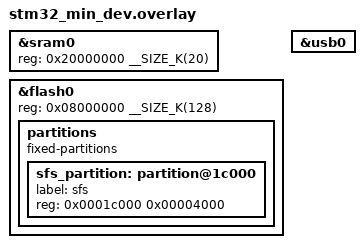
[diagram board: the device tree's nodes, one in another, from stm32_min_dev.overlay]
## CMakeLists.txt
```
include($ENV{ZEPHYR_BASE}/cmake/app/boilerplate.cmake NO_POLICY_SCOPE)
project(NONE)

add_definitions(-D_GLIBCXX_STDEXCEPT)

zephyr_include_directories(
  src
)

target_sources(app PRIVATE
  src/buf.c
  src/crypto.cpp
  src/hid.cpp
  src/main.cpp
  src/sfs.c
  src/u2f.cpp
  src/ui.cpp
  src/util.cpp
  src/crypto_sam0.cpp
)
```

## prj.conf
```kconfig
CONFIG_CPLUSPLUS=y
CONFIG_MAIN_STACK_SIZE=4096
CONFIG_SYSTEM_WORKQUEUE_STACK_SIZE=512
CONFIG_ISR_STACK_SIZE=1024

CONFIG_USB=y
CONFIG_USB_DEVICE_STACK=y
CONFIG_USB_DEVICE_HID=y

CONFIG_SYS_LOG=y
CONFIG_SYS_LOG_USB_DRIVER_LEVEL=1
CONFIG_SYS_LOG_USB_DEVICE_LEVEL=1

CONFIG_USB_DEVICE_VID=0x10c4
CONFIG_USB_DEVICE_PID=0x8acf
CONFIG_NET_BUF=y

CONFIG_INIT_STACKS=y

CONFIG_FLASH=y
CONFIG_SOC_FLASH_SAM0=y

CONFIG_DEBUG=y
CONFIG_ASSERT=y

CONFIG_FLASH_PAGE_LAYOUT=y
CONFIG_FILE_SYSTEM=y

CONFIG_MBEDTLS=y
CONFIG_MBEDTLS_BUILTIN=y
CONFIG_MBEDTLS_CFG_FILE="config-u2fzx.h"
CONFIG_MBEDTLS_ENABLE_HEAP=y
CONFIG_MBEDTLS_HEAP_SIZE=6500
```

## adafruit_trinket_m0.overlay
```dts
arduino_zero.overlay
```

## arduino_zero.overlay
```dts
&sercom0 {
	current-speed = <1000000>;
};

&flash0 {
	partitions {
		compatible = "fixed-partitions";
		#address-cells = <1>;
		#size-cells = <1>;

		sfs_partition: partition@3c000 {
			label = "sfs";
			reg = <0x0003c000 0x00004000>;
		};
	};
};
```

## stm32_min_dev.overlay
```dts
// / {
// 		zephyr,code-partition = &code_partition;
// };

&sram0 {
	reg = <0x20000000 __SIZE_K(20)>;
};

&flash0 {
	reg = <0x08000000 __SIZE_K(128)>;

	partitions {
		compatible = "fixed-partitions";
		#address-cells = <1>;
		#size-cells = <1>;

		// boot_partition: partition@0 {
		// 	label = "boot";
		// 	reg = <0x00000000 0x2000>;
		// 	read-only;
		// };

		// code_partition: partition@2000 {
		// 	label = "code";
		// 	reg = <0x2000 0x1a000>;
		// 	read-only;
		// };

		sfs_partition: partition@1c000 {
			label = "sfs";
			reg = <0x0001c000 0x00004000>;
		};
	};
};

&usb0 {
	status = "ok";
};
```

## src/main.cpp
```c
/*
 * Copyright 2018 Google LLC
 *
 * Licensed under the Apache License, Version 2.0 (the "License");
 * you may not use this file except in compliance with the License.
 * You may obtain a copy of the License at
 *
 *     https://www.apache.org/licenses/LICENSE-2.0
 *
 * Unless required by applicable law or agreed to in writing, software
 * distributed under the License is distributed on an "AS IS" BASIS,
 * WITHOUT WARRANTIES OR CONDITIONS OF ANY KIND, either express or implied.
 * See the License for the specific language governing permissions and
 * limitations under the License.
 *
 * SPDX-License-Identifier: Apache-2.0
 */

#define SYS_LOG_LEVEL 4
#define SYS_LOG_DOMAIN "main"
#include <logging/sys_log.h>

#include "crypto.h"
#include "ui.h"

#include <zephyr.h>

void hid_run();

void main(void)
{
	ui_wink(ui_code::STARTUP);

	/* The crypto init overwrites the seed.  Wait a little for the
	 * power to stabalise to reduce the change of losing the
	 * seed.
	 */
	k_sleep(K_MSEC(2670));

	auto err = u2f_crypto_init();
	if (err) {
		SYS_LOG_ERR("crypto=%d", err.code);
	}

	SYS_LOG_DBG("Starting application");
	ui_wink(ui_code::RUN);

	for (;;) {
		hid_run();
	}
}
```

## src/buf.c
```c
/*
 * Copyright 2018 Google LLC
 *
 * Licensed under the Apache License, Version 2.0 (the "License");
 * you may not use this file except in compliance with the License.
 * You may obtain a copy of the License at
 *
 *     https://www.apache.org/licenses/LICENSE-2.0
 *
 * Unless required by applicable law or agreed to in writing, software
 * distributed under the License is distributed on an "AS IS" BASIS,
 * WITHOUT WARRANTIES OR CONDITIONS OF ANY KIND, either express or implied.
 * See the License for the specific language governing permissions and
 * limitations under the License.
 *
 * SPDX-License-Identifier: Apache-2.0
 */

#include <net/buf.h>
#include <kernel.h>

void ui_thread(void *p1, void *p2, void *p3);

NET_BUF_POOL_DEFINE(hid_rx_pool, 1024/64, 64, 0, NULL);
NET_BUF_POOL_DEFINE(hid_msg_pool, 2, 700, 0, NULL);

K_THREAD_DEFINE(ui, 512, ui_thread, NULL, NULL, NULL, K_HIGHEST_THREAD_PRIO, 0, 0);
```

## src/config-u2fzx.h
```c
/*
 * Copyright 2018 Google LLC
 *
 * Licensed under the Apache License, Version 2.0 (the "License");
 * you may not use this file except in compliance with the License.
 * You may obtain a copy of the License at
 *
 *     https://www.apache.org/licenses/LICENSE-2.0
 *
 * Unless required by applicable law or agreed to in writing, software
 * distributed under the License is distributed on an "AS IS" BASIS,
 * WITHOUT WARRANTIES OR CONDITIONS OF ANY KIND, either express or implied.
 * See the License for the specific language governing permissions and
 * limitations under the License.
 *
 * SPDX-License-Identifier: Apache-2.0
 */

#ifndef MBEDTLS_CONFIG_H
#define MBEDTLS_CONFIG_H

extern void *stderr;
void u2f_fprintf(void *, const char *, ...);

/* System support */
#define MBEDTLS_PLATFORM_C
#define MBEDTLS_PLATFORM_MEMORY
#define MBEDTLS_MEMORY_BUFFER_ALLOC_C
#define MBEDTLS_PLATFORM_NO_STD_FUNCTIONS
#define MBEDTLS_PLATFORM_EXIT_ALT
#define MBEDTLS_NO_PLATFORM_ENTROPY
//#define MBEDTLS_NO_DEFAULT_ENTROPY_SOURCES
#define MBEDTLS_PLATFORM_PRINTF_ALT
#define MBEDTLS_ENTROPY_C
#define MBEDTLS_TIMING_C
#define MBEDTLS_TIMING_ALT
#define MBEDTLS_ENTROPY_NV_SEED
#define MBEDTLS_MEMORY_DEBUG
#define MBEDTLS_HAVE_ASM
#define MBEDTLS_PLATFORM_FPRINTF_MACRO u2f_fprintf

/* mbed TLS feature support */
#define MBEDTLS_AES_ROM_TABLES
#define MBEDTLS_ECP_DP_SECP256R1_ENABLED
#define MBEDTLS_ECP_NIST_OPTIM

/* mbed TLS modules */
#define MBEDTLS_AES_C
#define MBEDTLS_ASN1_PARSE_C
#define MBEDTLS_ASN1_WRITE_C
#define MBEDTLS_BIGNUM_C
//#define MBEDTLS_CCM_C
#define MBEDTLS_CIPHER_C
#define MBEDTLS_CTR_DRBG_C
//#define MBEDTLS_CMAC_C
//#define MBEDTLS_ECJPAKE_C
#define MBEDTLS_ECP_C
//#define MBEDTLS_HMAC_DRBG_C
//#define MBEDTLS_MD_C
//#define MBEDTLS_OID_C
#define MBEDTLS_SHA256_C
#define MBEDTLS_ECDSA_C

/* Save RAM at the expense of ROM */
#define MBEDTLS_AES_ROM_TABLES

/* Save RAM by adjusting to our exact needs */
#define MBEDTLS_ECP_MAX_BITS 256
#define MBEDTLS_MPI_MAX_SIZE 32 // 256 bits is 32 bytes

unsigned int mbedtls_timing_hardclock(void);
int mbedtls_platform_std_nv_seed_read(unsigned char *buf,
				      unsigned int buf_len);
int mbedtls_platform_std_nv_seed_write(unsigned char *buf,
				       unsigned int buf_len);

#include "mbedtls/check_config.h"

#endif /* MBEDTLS_CONFIG_H */
```

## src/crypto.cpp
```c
/*
 * Copyright 2018 Google LLC
 *
 * Licensed under the Apache License, Version 2.0 (the "License");
 * you may not use this file except in compliance with the License.
 * You may obtain a copy of the License at
 *
 *     https://www.apache.org/licenses/LICENSE-2.0
 *
 * Unless required by applicable law or agreed to in writing, software
 * distributed under the License is distributed on an "AS IS" BASIS,
 * WITHOUT WARRANTIES OR CONDITIONS OF ANY KIND, either express or implied.
 * See the License for the specific language governing permissions and
 * limitations under the License.
 *
 * SPDX-License-Identifier: Apache-2.0
 */

#define SYS_LOG_LEVEL 4
#define SYS_LOG_DOMAIN "crypto"
#include <logging/sys_log.h>

#include "crypto.h"
#include "sfs.h"
#include "util.h"

#include <algorithm>

#define U2F_SEED "/seed"

extern "C" {
#include <mbedtls/ctr_drbg.h>
#include <mbedtls/ecdsa.h>
#include <mbedtls/ecp.h>
#include <mbedtls/entropy.h>
#include <mbedtls/sha256.h>
}

struct crypto {
	mbedtls_entropy_context entropy;
	mbedtls_ctr_drbg_context ctr_drbg;
};

static crypto crypto;

size_t u2f_base64url(const gsl::span<u8_t> src, gsl::span<char> dest)
{
	static const char alphabet[] = "ABCDEFGHIJKLMNOP"
				       "QRSTUVWXYZabcdef"
				       "ghijklmnopqrstuv"
				       "wxyz0123456789-_";
	size_t out = src.size() * 4 / 3;

	if ((src.size() % 3) != 0 || dest.size() < out) {
		return 0;
	}

	char *p = dest.begin();
	for (size_t i = 0; i < src.size(); i += 3) {
		const auto s = src.cbegin();
		u32_t acc = (s[i + 2] << 16) | (s[i + 1] << 8) | (s[i + 0]);

		for (size_t j = 0; j < 4; j++) {
			*p++ = alphabet[acc % 64];
			acc >>= 6;
		}
	}

	return p - dest.begin();
}

int u2f_mbedtls_rng(void *ctx, u8_t *buf, size_t len)
{
	return mbedtls_ctr_drbg_random(&crypto.ctr_drbg, buf, len);
}

error u2f_rng(gsl::span<u8_t> dest)
{
	return error(u2f_mbedtls_rng(nullptr, dest.begin(), dest.size()));
}

int mbedtls_platform_std_nv_seed_read(u8_t *buf, size_t len)
{
	struct sfs_file fp;

	SYS_LOG_DBG("len=%d", len);

	std::fill(buf, buf + len, 0x55);

	auto err = sfs_open(&fp, U2F_SEED);
	if (err != 0) {
		SYS_LOG_DBG("open");
		return 0;
	}

	auto got = sfs_read(&fp, buf, len);
	if (got < 0) {
		SYS_LOG_DBG("read");
		return 0;
	}
	if ((size_t)got != len) {
		SYS_LOG_DBG("short");
		return 0;
	}
	return 0;
}

int mbedtls_platform_std_nv_seed_write(u8_t *buf, size_t len)
{
	struct sfs_file fp;
	int err;

	SYS_LOG_DBG("len=%d", len);

	err = sfs_open(&fp, U2F_SEED);
	if (err != 0) {
		SYS_LOG_DBG("open");
		return err;
	}

	auto wrote = sfs_write(&fp, buf, len);
	if (wrote < 0) {
		SYS_LOG_DBG("write");
		return wrote;
	}
	if ((size_t)wrote != len) {
		SYS_LOG_DBG("short");
		return -EIO;
	}
	return 0;
}

error u2f_crypto_init()
{
	mbedtls_entropy_init(&crypto.entropy);
	mbedtls_ctr_drbg_init(&crypto.ctr_drbg);

	auto custom = u2f_crypto_custom();
	return error(mbedtls_ctr_drbg_seed(&crypto.ctr_drbg,
					   mbedtls_entropy_func,
					   &crypto.entropy,
					   (u8_t*)custom.data(), custom.size()*sizeof(custom.data()[0])));
}

void *stderr;

extern "C" void u2f_fprintf(void *ignore, const char *fmt, ...)
{
	va_list ap;

	va_start(ap, fmt);
	vprintk(fmt, ap);
	va_end(ap);
}
```

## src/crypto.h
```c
/*
 * Copyright 2018 Google LLC
 *
 * Licensed under the Apache License, Version 2.0 (the "License");
 * you may not use this file except in compliance with the License.
 * You may obtain a copy of the License at
 *
 *     https://www.apache.org/licenses/LICENSE-2.0
 *
 * Unless required by applicable law or agreed to in writing, software
 * distributed under the License is distributed on an "AS IS" BASIS,
 * WITHOUT WARRANTIES OR CONDITIONS OF ANY KIND, either express or implied.
 * See the License for the specific language governing permissions and
 * limitations under the License.
 *
 * SPDX-License-Identifier: Apache-2.0
 */

#pragma once

#include "util.h"

#include <array>

int u2f_mbedtls_rng(void *ctx, u8_t *buf, size_t len);

size_t u2f_base64url(const gsl::span<u8_t> src, gsl::span<char> dest);
error u2f_rng(gsl::span<u8_t> dest);
std::array<u32_t, 6> u2f_crypto_custom();

error u2f_crypto_init();
```

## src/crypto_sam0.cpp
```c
/*
 * Copyright 2018 Google LLC
 *
 * Licensed under the Apache License, Version 2.0 (the "License");
 * you may not use this file except in compliance with the License.
 * You may obtain a copy of the License at
 *
 *     https://www.apache.org/licenses/LICENSE-2.0
 *
 * Unless required by applicable law or agreed to in writing, software
 * distributed under the License is distributed on an "AS IS" BASIS,
 * WITHOUT WARRANTIES OR CONDITIONS OF ANY KIND, either express or implied.
 * See the License for the specific language governing permissions and
 * limitations under the License.
 *
 * SPDX-License-Identifier: Apache-2.0
 */

#include <string.h>
#include <zephyr.h>

#include "crypto.h"
#include <arch/arm/cortex_m/cmsis.h>

extern "C" {
#include <mbedtls/entropy.h>
}

#define SERIAL_0 0x0080A00C
#define SERIAL_1 0x0080A040
#define SERIAL_2 0x0080A044
#define SERIAL_3 0x0080A048

std::array<u32_t, 6> u2f_crypto_custom()
{
	std::array<u32_t, 6> c;

	std::fill(c.begin(), c.end(), 0);
	c[0] = *(u32_t *)SERIAL_0;
	c[1] = *(u32_t *)SERIAL_1;
	c[2] = *(u32_t *)SERIAL_2;
	c[3] = *(u32_t *)SERIAL_3;

	return c;
}

u32_t mbedtls_timing_hardclock() {
	printk("mbedtls_timing_hardclock\n");

	return SysTick->VAL;
}
```

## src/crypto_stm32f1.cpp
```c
/*
 * Copyright 2018 Google LLC
 *
 * Licensed under the Apache License, Version 2.0 (the "License");
 * you may not use this file except in compliance with the License.
 * You may obtain a copy of the License at
 *
 *     https://www.apache.org/licenses/LICENSE-2.0
 *
 * Unless required by applicable law or agreed to in writing, software
 * distributed under the License is distributed on an "AS IS" BASIS,
 * WITHOUT WARRANTIES OR CONDITIONS OF ANY KIND, either express or implied.
 * See the License for the specific language governing permissions and
 * limitations under the License.
 *
 * SPDX-License-Identifier: Apache-2.0
 */

#include <string.h>
#include <zephyr.h>

#include "crypto.h"
#include <arch/arm/cortex_m/cmsis.h>

extern "C" {
#include <mbedtls/entropy.h>
}

std::array<u32_t, 6> u2f_crypto_custom()
{
	std::array<u32_t, 6> c;

	std::fill(c.begin(), c.end(), 0);

	return c;
}

u32_t mbedtls_timing_hardclock() {
	printk("mbedtls_timing_hardclock\n");

	return SysTick->VAL;
}
```

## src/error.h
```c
/*
 * Copyright (c) 2018 Google LLC.
 *
 * SPDX-License-Identifier: Apache-2.0
 */

#pragma once

#include <errno.h>
#include <zephyr/types.h>

#define ERROR(_code) { .code = static_cast<s16_t>(_code) }

struct error {
	error() : code(0) {}
	error(int status) : code(status) {}

	explicit operator bool() const { return code != 0; }

	s16_t code;

	struct proxy {
		s16_t code;
	};

	error(proxy p) : code(p.code) {}

	static constexpr struct proxy ok = ERROR(0);
	static constexpr struct proxy io = ERROR(-EIO);
	static constexpr struct proxy noent = ERROR(-ENOENT);
	static constexpr struct proxy nomem = ERROR(-ENOMEM);
	static constexpr struct proxy inval = ERROR(-EINVAL);
	static constexpr struct proxy exist = ERROR(-EEXIST);
	static constexpr struct proxy perm = ERROR(-EPERM);
};
```

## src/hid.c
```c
/*
 * Copyright (c) 2018 Google LLC.
 *
 * SPDX-License-Identifier: Apache-2.0
 */

#define SYS_LOG_LEVEL 4
#define SYS_LOG_DOMAIN "hid"
#include <logging/sys_log.h>

#include <misc/byteorder.h>
#include <net/buf.h>
#include <string.h>
#include <zephyr.h>
#include <device.h>
#include <init.h>

#include <usb/usb_device.h>
#include <usb/class/usb_hid.h>

#include "prng.h"

#define TYPE_MASK 0x80
#define TYPE_INIT 0x80
#define TYPE_CONT 0x00

#define U2FHID_PING (TYPE_INIT | 0x01)
#define U2FHID_MSG (TYPE_INIT | 0x03)
#define U2FHID_LOCK (TYPE_INIT | 0x04)
#define U2FHID_INIT (TYPE_INIT | 0x06)
#define U2FHID_WINK (TYPE_INIT | 0x08)
#define U2FHID_ERROR (TYPE_INIT | 0x3f)

#define CAPABILITY_WINK 0x01
#define CAPABILITY_LOCK 0x02

#define U2FHID_BROADCAST 0xffffffff

#define U2FHID_PACKET_SIZE 64
#define U2FHID_INIT_PAYLOAD_SIZE (U2FHID_PACKET_SIZE - 7)
#define U2FHID_CONT_PAYLOAD_SIZE (U2FHID_PACKET_SIZE - 5)
#define U2FHID_MAX_PAYLOAD_SIZE (7609)

void dump_hex(const char *msg, const u8_t *buf, int len);
int u2f_dispatch(struct net_buf *req, struct net_buf *resp);

struct u2f_init_hdr {
	u32_t cid;
	u8_t cmd;
	u8_t bcnt[2];
	u8_t payload[1];
};
BUILD_ASSERT(sizeof(struct u2f_init_hdr) == 8);

struct u2f_init_pkt {
	u32_t cid;
	u8_t cmd;
	u8_t bcnt[2];
	u8_t payload[U2FHID_INIT_PAYLOAD_SIZE];
};
BUILD_ASSERT(sizeof(struct u2f_init_pkt) == U2FHID_PACKET_SIZE);

struct u2f_cont_pkt {
	u32_t cid;
	u8_t seq;
	u8_t payload[U2FHID_CONT_PAYLOAD_SIZE];
};
BUILD_ASSERT(sizeof(struct u2f_cont_pkt) == U2FHID_PACKET_SIZE);

struct hid_data {
	u32_t next_channel;
	u32_t cid;

	struct net_buf *rx;
	u32_t rx_cid;
	u8_t rx_cmd;
	u16_t rx_want;
	u8_t rx_seq;
	struct k_work rx_work;
	struct k_fifo rx_q;

	struct k_fifo tx_q;
	struct k_work tx_work;

	struct net_buf *tx;
	int tx_seq;
};

static struct hid_data data;

NET_BUF_POOL_DEFINE(hid_msg_pool, 4, 700, 0, NULL);

/* Some HID sample Report Descriptor */
static const u8_t hid_report_desc[] = {
	0x06, 0xd0,
	0xf1,       /* USAGE_PAGE (FIDO Alliance) */
	0x09, 0x01, /* USAGE (Keyboard) */
	0xa1, 0x01, /* COLLECTION (Application) */

	0x09, 0x20, /* USAGE (Input Report Data) */
	0x15, 0x00, /* LOGICAL_MINIMUM (0) */
	0x26, 0xff,
	0x00,			  /* LOGICAL_MAXIMUM (255) */
	0x75, 0x08,		  /* REPORT_SIZE (8) */
	0x95, U2FHID_PACKET_SIZE, /* REPORT_COUNT (64) */
	0x81, 0x02,		  /* INPUT (Data,Var,Abs) */
	0x09, 0x21,		  /* USAGE(Output Report Data) */
	0x15, 0x00,		  /* LOGICAL_MINIMUM (0) */
	0x26, 0xff,
	0x00,			  /* LOGICAL_MAXIMUM (255) */
	0x75, 0x08,		  /* REPORT_SIZE (8) */
	0x95, U2FHID_PACKET_SIZE, /* REPORT_COUNT (64) */
	0x91, 0x02,		  /* OUTPUT (Data,Var,Abs) */

	0xc0, /* END_COLLECTION */
};

static void hid_tx(struct k_work *work)
{
	int err;
	u32_t wrote;
	int at;
	int stride;

	if (data.tx == NULL) {
		data.tx = net_buf_get(&data.tx_q, K_NO_WAIT);
		data.tx_seq = -1;
	}
	if (data.tx == NULL) {
		SYS_LOG_DBG("done");
		return;
	}

	if (data.tx_seq < 0) {
		at = 0;
		stride = U2FHID_PACKET_SIZE;
		err = usb_write(CONFIG_HID_INT_EP_ADDR, data.tx->data,
				U2FHID_PACKET_SIZE, &wrote);
	} else {
		struct u2f_cont_pkt pkt = {
			.cid = *(u32_t *)(data.tx->data), .seq = data.tx_seq,
		};

		at = U2FHID_PACKET_SIZE +
		     (data.tx_seq * U2FHID_CONT_PAYLOAD_SIZE);
		stride = U2FHID_CONT_PAYLOAD_SIZE;
		memcpy(pkt.payload, data.tx->data + at, stride);
		err = usb_write(CONFIG_HID_INT_EP_ADDR, (u8_t *)&pkt,
				sizeof(pkt), &wrote);
	}

	if (err == 0) {
		prng_feed();

		data.tx_seq++;
		if (at + stride >= data.tx->len) {
			net_buf_unref(data.tx);
			data.tx = NULL;
		}
	}

	k_work_submit(&data.tx_work);
}

static int hid_handle_init(struct net_buf *req, struct net_buf *resp)
{
	SYS_LOG_DBG("");

	net_buf_add_mem(resp, req->data, 8);
	net_buf_pull(req, 8);
	net_buf_add_be32(resp, ++data.next_channel);
	net_buf_add_u8(resp, 2);
	net_buf_add_u8(resp, 0);
	net_buf_add_u8(resp, 1);
	net_buf_add_u8(resp, 0);
	net_buf_add_u8(resp, CAPABILITY_WINK);

	return 0;
}

static void hid_rx(struct k_work *work)
{
	struct net_buf *req;
	struct net_buf *resp = NULL;
	struct u2f_init_hdr *hdr;
	u8_t *bcnt;
	int err = 0;

	SYS_LOG_DBG("");

	req = k_fifo_get(&data.rx_q, K_NO_WAIT);
	if (req == NULL) {
		goto done;
	}

	dump_hex("<<", req->data, req->len);

	hdr = (struct u2f_init_hdr *)req->data;
	net_buf_pull(req, offsetof(struct u2f_init_hdr, payload));

	SYS_LOG_DBG("cid=%x cmd=%x", hdr->cid, hdr->cmd);

	resp = net_buf_alloc(&hid_msg_pool, K_NO_WAIT);
	if (resp == NULL) {
		err = -ENOMEM;
		goto done;
	}

	net_buf_add_mem(resp, &hdr->cid, sizeof(hdr->cid));
	net_buf_add_u8(resp, hdr->cmd);
	bcnt = net_buf_add(resp, 2);

	switch (hdr->cmd) {
	case U2FHID_INIT:
		err = hid_handle_init(req, resp);
		break;
	case U2FHID_MSG:
		err = u2f_dispatch(req, resp);
		break;
	default:
		err = -EINVAL;
	}

	if (err != 0) {
		goto done;
	}

	sys_put_be16(resp->len - 4 - 1 - 2, bcnt);

	dump_hex(">>", resp->data, resp->len);
	net_buf_ref(resp);
	net_buf_put(&data.tx_q, resp);
	k_work_submit(&data.tx_work);

done:
	if (resp != NULL) {
		net_buf_unref(resp);
	}
	if (req != NULL) {
		net_buf_unref(req);
	}
	if (!k_fifo_is_empty(&data.rx_q)) {
		k_work_submit(work);
	}
}

static int hid_set_report_cb(struct usb_setup_packet *setup, s32_t *plen,
			     u8_t **pdata)
{
	struct u2f_init_pkt *pkt = (struct u2f_init_pkt *)*pdata;
	int len = *plen;

	prng_feed();

	if (len < offsetof(struct u2f_cont_pkt, payload)) {
		return -EINVAL;
	}
	if ((pkt->cmd & TYPE_INIT) != 0) {
		u16_t bcnt;

		if (len < offsetof(struct u2f_init_pkt, payload)) {
			SYS_LOG_ERR("init packet too short");
			return -EINVAL;
		}
		bcnt = sys_get_be16(pkt->bcnt);
		if (bcnt > U2FHID_MAX_PAYLOAD_SIZE) {
			SYS_LOG_ERR("bcnt too big");
			return -EINVAL;
		}

		SYS_LOG_DBG("cmd=%x bcnt=%d", pkt->cmd, bcnt);
		if (data.rx != NULL) {
			net_buf_unref(data.rx);
			data.rx = NULL;
		}

		data.rx = net_buf_alloc(&hid_msg_pool, K_NO_WAIT);
		if (data.rx == NULL) {
			SYS_LOG_ERR("No memory");
			return -ENOMEM;
		}

		data.rx_cid = pkt->cid;
		data.rx_want = bcnt + offsetof(struct u2f_init_pkt, payload);
		data.rx_seq = 0;

		net_buf_add_mem(data.rx, (u8_t *)pkt, len);
	} else {
		struct u2f_cont_pkt *cont = (struct u2f_cont_pkt *)*pdata;

		if (data.rx == NULL) {
			SYS_LOG_ERR("no rx buf");
			return -EINVAL;
		}
		if (cont->cid != data.rx_cid) {
			SYS_LOG_ERR("cid changed");
			return -EINVAL;
		}
		if (cont->seq != data.rx_seq) {
			SYS_LOG_ERR("seq out of order");
			return -EINVAL;
		}
		data.rx_seq = cont->seq + 1;
		SYS_LOG_DBG("seq=%x", cont->seq);

		net_buf_add_mem(data.rx, cont->payload, len - 5);
	}

	if (data.rx != NULL && data.rx->len >= data.rx_want) {
		SYS_LOG_DBG("dispatch");
		net_buf_put(&data.rx_q, data.rx);
		data.rx = NULL;
		k_work_submit(&data.rx_work);
	}

	return 0;
}

static int hid_get_report_cb(struct usb_setup_packet *setup, s32_t *len,
			     u8_t **data)
{
	SYS_LOG_DBG("Get report callback");
	return 0;
}

static struct hid_ops ops = {
	.get_report = hid_get_report_cb,
	.set_report = hid_set_report_cb,
};

static int hid_init(struct device *dev)
{
	k_fifo_init(&data.rx_q);
	k_fifo_init(&data.tx_q);
	k_work_init(&data.tx_work, hid_tx);
	k_work_init(&data.rx_work, hid_rx);

	usb_hid_register_device(hid_report_desc, sizeof(hid_report_desc),
				&ops);
	return usb_hid_init();
}

SYS_INIT(hid_init, APPLICATION, CONFIG_APPLICATION_INIT_PRIORITY);
```

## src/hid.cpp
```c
/*
 * Copyright 2018 Google LLC
 *
 * Licensed under the Apache License, Version 2.0 (the "License");
 * you may not use this file except in compliance with the License.
 * You may obtain a copy of the License at
 *
 *     https://www.apache.org/licenses/LICENSE-2.0
 *
 * Unless required by applicable law or agreed to in writing, software
 * distributed under the License is distributed on an "AS IS" BASIS,
 * WITHOUT WARRANTIES OR CONDITIONS OF ANY KIND, either express or implied.
 * See the License for the specific language governing permissions and
 * limitations under the License.
 *
 * SPDX-License-Identifier: Apache-2.0
 */

#define SYS_LOG_LEVEL 4
#define SYS_LOG_DOMAIN "hid"
#include <logging/sys_log.h>

#include <device.h>
#include <init.h>
#include <misc/byteorder.h>
#include <net/buf.h>
#include <string.h>
#include <zephyr.h>

#include <usb/class/usb_hid.h>
#include <usb/usb_device.h>

#include "ui.h"
#include "util.h"

#include <algorithm>

#define TYPE_MASK 0x80
#define TYPE_INIT 0x80
#define TYPE_CONT 0x00

enum class u2fhid_cmd : u8_t {
	PING = TYPE_INIT | 0x01,
	MSG = TYPE_INIT | 0x03,
	LOCK = TYPE_INIT | 0x04,
	INIT = TYPE_INIT | 0x06,
	WINK = TYPE_INIT | 0x08,
	ERROR = TYPE_INIT | 0x3f,
};

enum class u2fhid_err : u8_t {
	/* No error */
	NONE = 0x00,
	/* Invalid command */
	INVALID_CMD = 0x01,
	/* Invalid parameter */
	INVALID_PAR = 0x02,
	/* Invalid message length */
	INVALID_LEN = 0x03,
	/* Invalid message sequencing */
	INVALID_SEQ = 0x04,
	/* Message has timed out */
	MSG_TIMEOUT = 0x05,
	/* Channel busy */
	CHANNEL_BUSY = 0x06,
	/* Command requires channel lock */
	LOCK_REQUIRED = 0x0a,
	/* Command not allowed on this cid */
	INVALID_CID = 0x0b,
	/* Other unspecified error */
	OTHER = 0x7f,
};

#define CAPABILITY_WINK 0x01
#define CAPABILITY_LOCK 0x02

#define U2FHID_BROADCAST 0xffffffff

#define U2FHID_PACKET_SIZE 64
#define U2FHID_INIT_PAYLOAD_SIZE (U2FHID_PACKET_SIZE - 7)
#define U2FHID_CONT_PAYLOAD_SIZE (U2FHID_PACKET_SIZE - 5)
#define U2FHID_MAX_PAYLOAD_SIZE (7609)

extern struct net_buf_pool hid_msg_pool;
extern struct net_buf_pool hid_rx_pool;

error u2f_dispatch(struct net_buf *req, struct net_buf *resp);

struct u2f_init_hdr {
	u32_t cid;
	u2fhid_cmd cmd;
	u8_t bcnt[2];
	u8_t payload[1];
};
BUILD_ASSERT(sizeof(struct u2f_init_hdr) == 8);

struct u2f_init_pkt {
	u32_t cid;
	u2fhid_cmd cmd;
	u8_t bcnt[2];
	u8_t payload[U2FHID_INIT_PAYLOAD_SIZE];
};
BUILD_ASSERT(sizeof(struct u2f_init_pkt) == U2FHID_PACKET_SIZE);

struct u2f_cont_pkt {
	u32_t cid;
	u8_t seq;
	u8_t payload[U2FHID_CONT_PAYLOAD_SIZE];
};
BUILD_ASSERT(sizeof(struct u2f_cont_pkt) == U2FHID_PACKET_SIZE);

struct hid_data {
	u32_t next_channel;
	u32_t cid;

	struct k_fifo rx_q;
	struct k_sem tx_sem;
};

static struct hid_data data;

/* Some HID sample Report Descriptor */
static const u8_t hid_report_desc[] = {
	0x06, 0xd0,
	0xf1,       /* USAGE_PAGE (FIDO Alliance) */
	0x09, 0x01, /* USAGE (Keyboard) */
	0xa1, 0x01, /* COLLECTION (Application) */

	0x09, 0x20, /* USAGE (Input Report Data) */
	0x15, 0x00, /* LOGICAL_MINIMUM (0) */
	0x26, 0xff,
	0x00,			  /* LOGICAL_MAXIMUM (255) */
	0x75, 0x08,		  /* REPORT_SIZE (8) */
	0x95, U2FHID_PACKET_SIZE, /* REPORT_COUNT (64) */
	0x81, 0x02,		  /* INPUT (Data,Var,Abs) */
	0x09, 0x21,		  /* USAGE(Output Report Data) */
	0x15, 0x00,		  /* LOGICAL_MINIMUM (0) */
	0x26, 0xff,
	0x00,			  /* LOGICAL_MAXIMUM (255) */
	0x75, 0x08,		  /* REPORT_SIZE (8) */
	0x95, U2FHID_PACKET_SIZE, /* REPORT_COUNT (64) */
	0x91, 0x02,		  /* OUTPUT (Data,Var,Abs) */

	0xc0, /* END_COLLECTION */
};

struct autounref {
	autounref(struct net_buf *b) : buf_{b} {}
	~autounref()
	{
		if (buf_ != nullptr) {
			net_buf_unref(buf_);
			buf_ = nullptr;
		}
	}

      private:
	struct net_buf *buf_;
};

static error hid_handle_init(struct net_buf *req, struct net_buf *resp)
{
	net_buf_add_mem(resp, req->data, 8);
	net_buf_pull(req, 8);
	net_buf_add_be32(resp, ++data.next_channel);
	net_buf_add_u8(resp, 2);
	net_buf_add_u8(resp, 0);
	net_buf_add_u8(resp, 1);
	net_buf_add_u8(resp, 0);
	net_buf_add_u8(resp, CAPABILITY_WINK);

	return error::ok;
}

static net_buf *hid_rx_pkt(u8_t type, int min_size, int timeout)
{
	auto rx = net_buf_get(&data.rx_q, timeout);
	autounref rx1{rx};

	if (rx == nullptr) {
		return nullptr;
	}
	u2f_dump_hex("<<", rx->data, rx->len);

	if (rx->len < min_size) {
		return nullptr;
	}

	auto hdr = (u2f_init_hdr *)rx->data;
	if ((static_cast<u8_t>(hdr->cmd) & TYPE_MASK) != type) {
		return nullptr;
	}

	net_buf_ref(rx);

	return rx;
}

static net_buf *hid_rx(u32_t &cid, u2fhid_cmd &cmd)
{
	auto rx = hid_rx_pkt(TYPE_INIT, sizeof(u2f_init_hdr), K_FOREVER);
	autounref rx1{rx};

	if (rx == nullptr) {
		return nullptr;
	}

	auto hdr = (u2f_init_pkt *)rx->data;
	cid = hdr->cid;
	cmd = hdr->cmd;

	auto req = net_buf_alloc(&hid_msg_pool, K_NO_WAIT);
	autounref req1{req};

	if (req == nullptr) {
		/* No buffers */
		SYS_LOG_ERR("unable to make a req buffer");
		return nullptr;
	}

	auto bcnt = sys_get_be16(hdr->bcnt);
	if (bcnt > req->size) {
		SYS_LOG_ERR("bcnt=%d is too big for buf %d", bcnt, req->size);
		return nullptr;
	}

	size_t remain = bcnt;
	/* Take everything from the first packet */
	size_t take =
		std::min(remain, rx->len - offsetof(u2f_init_pkt, payload));
	net_buf_add_mem(req, hdr->payload, take);
	remain -= take;

	SYS_LOG_DBG("took %d of bcnt=%d from 1st packet", take, bcnt);

	for (u8_t seq = 0; remain > 0; seq++) {
		auto crx =
			hid_rx_pkt(TYPE_CONT, offsetof(u2f_cont_pkt, payload),
				   K_SECONDS(1));
		autounref crx1{crx};

		if (crx == nullptr) {
			SYS_LOG_WRN("timeout while waiting for cont packet");
			return nullptr;
		}

		auto cont = (u2f_cont_pkt *)crx->data;
		if (cont->seq != seq) {
			SYS_LOG_WRN("got seq=%d expect %d on cont packet",
				    cont->seq, seq);
			return nullptr;
		}

		take = std::min(remain,
				crx->len - offsetof(u2f_cont_pkt, payload));
		net_buf_add_mem(req, cont->payload, take);
		SYS_LOG_DBG("took %d of remain=%d from seq=%d", take, remain,
			    seq);

		remain -= take;
	}

	net_buf_ref(req);
	return req;
}

static u2fhid_err hid_map_error(error err)
{
	switch (err.code) {
	case 0:
	case -ENOENT:
		return u2fhid_err::INVALID_CMD;
	default:
		SYS_LOG_ERR("unmapped error code=%d", err.code);
		return u2fhid_err::OTHER;
	}
}

static error hid_tx_pkt(const u8_t *buf, int len)
{
	for (int retry = 0; retry < 10; retry++) {
		u32_t wrote = 0;
		error err = ERROR(
			usb_write(CONFIG_HID_INT_EP_ADDR, buf, len, &wrote));

		switch (err.code) {
		case 0:
			return err;
		case -EAGAIN:
			k_sem_take(&data.tx_sem, K_MSEC(100));
			break;
		default:
			SYS_LOG_ERR("err=%d", err.code);
			return err;
		}
	}

	SYS_LOG_ERR("timeout");
	return error::io;
}

static void hid_tx(u32_t cid, u2fhid_cmd cmd, net_buf *resp)
{
	u32_t start = k_uptime_get_32();

	size_t bcnt = resp->len;
	const u8_t *p = resp->data;

	{
		u2f_init_pkt init = {
			.cid = cid,
			.cmd = cmd,
		};

		sys_put_be16(bcnt, init.bcnt);

		size_t take = std::min(sizeof(init.payload), bcnt);
		std::copy(p, p + take, init.payload);

		SYS_LOG_DBG("writing %d of %d in 1st packet", take, bcnt);

		if (hid_tx_pkt((u8_t *)&init, sizeof(init))) {
			return;
		}
		bcnt -= take;
		p += take;
	}

	for (u8_t seq = 0; bcnt > 0; seq++) {
		u2f_cont_pkt cont = {
			.cid = cid,
			.seq = seq,
		};

		int take = std::min(sizeof(cont.payload), bcnt);
		std::copy(p, p + take, cont.payload);

		if (hid_tx_pkt((u8_t *)&cont, sizeof(cont))) {
			return;
		}

		bcnt -= take;
		p += take;
	}

	SYS_LOG_DBG("tx in %d", (int)(k_uptime_get_32() - start));
}

void hid_run()
{
	/* Receive a packet and ensure it's released later. */
	u32_t cid = 0;
	u2fhid_cmd cmd = u2fhid_cmd::ERROR;

	auto req = hid_rx(cid, cmd);
	autounref req1{req};

	if (req == nullptr) {
		return;
	}

	/* Allocate the response buf. */
	auto resp = net_buf_alloc(&hid_msg_pool, K_NO_WAIT);
	autounref resp1{resp};

	if (resp == nullptr) {
		return;
	}

	error err;

	switch (cmd) {
	case u2fhid_cmd::INIT:
		err = hid_handle_init(req, resp);
		break;
	case u2fhid_cmd::MSG:
		err = u2f_dispatch(req, resp);
		break;
	case u2fhid_cmd::WINK:
		ui_wink(ui_code::AUTO);
		err = error::ok;
		break;
	default:
		err = ERROR(-ENOENT);
		break;
	}

	if (err) {
		net_buf_reset(resp);
		net_buf_add_u8(resp,
			       static_cast<u8_t>(hid_map_error(err)));
		hid_tx(cid, u2fhid_cmd::ERROR, resp);
	} else {
		hid_tx(cid, cmd, resp);
	}
}

static int hid_set_report_cb(struct usb_setup_packet *setup, s32_t *plen,
			     u8_t **pdata)
{
	size_t len = *plen;

	auto buf = net_buf_alloc(&hid_rx_pool, K_NO_WAIT);
	if (buf == nullptr) {
		return -ENOMEM;
	}
	if (len > net_buf_tailroom(buf)) {
		net_buf_unref(buf);
		return -ENOMEM;
	}

	net_buf_add_mem(buf, *pdata, len);
	net_buf_put(&data.rx_q, buf);

	return 0;
}

static int hid_get_report_cb(struct usb_setup_packet *setup, s32_t *len,
			     u8_t **data)
{
	SYS_LOG_DBG("Get report callback");
	return 0;
}

static void hid_int_in_ready(void) { k_sem_give(&data.tx_sem); }

static struct hid_ops ops = {
	.get_report = hid_get_report_cb,
	.get_idle = nullptr,
	.get_protocol = nullptr,
	.set_report = hid_set_report_cb,
	.set_idle = nullptr,
	.set_protocol = nullptr,
	.int_in_ready = hid_int_in_ready,
};

static int hid_init(struct device *dev)
{
	k_fifo_init(&data.rx_q);
	k_sem_init(&data.tx_sem, 1, 2);

	usb_hid_register_device(hid_report_desc, sizeof(hid_report_desc),
				&ops);
	return usb_hid_init();
}

SYS_INIT(hid_init, APPLICATION, CONFIG_APPLICATION_INIT_PRIORITY);
```

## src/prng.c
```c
/*
 * Copyright (c) 2018 Google LLC.
 *
 * SPDX-License-Identifier: Apache-2.0
 */

#include <device.h>
#include <init.h>
#include <misc/byteorder.h>
#include <net/buf.h>
#include <string.h>
#include <zephyr.h>

#include <tinycrypt/constants.h>
#include <tinycrypt/hmac_prng.h>

#include "prng.h"

struct prng_data {
	struct tc_hmac_prng_struct prng;
	u32_t entropy[17];
	u8_t at;
};

static struct prng_data data;

void prng_add_entropy(u32_t ch)
{
	data.entropy[data.at++] = ch;
	if (data.at >= ARRAY_SIZE(data.entropy)) {
		data.at = 0;
	}
}

int default_CSPRNG(u8_t *buf, unsigned int len)
{
	int err;

	for (;;) {
		err = tc_hmac_prng_generate(buf, len, &data.prng);

		switch (err) {
		case TC_CRYPTO_SUCCESS:
			return err;
		case TC_HMAC_PRNG_RESEED_REQ:
			prng_feed();
			err = tc_hmac_prng_reseed(
				&data.prng, (u8_t *)data.entropy,
				sizeof(data.entropy), NULL, 0);
			if (err != TC_CRYPTO_SUCCESS) {
				return err;
			}
			break;
		default:
			return TC_CRYPTO_FAIL;
		}
	}
}

static int prng_init(struct device *dev)
{
	int err;

	prng_board_init();

	err = tc_hmac_prng_init(&data.prng, (u8_t *)data.entropy,
				sizeof(data.entropy));
	if (err != TC_CRYPTO_SUCCESS) {
		return -ENOMEM;
	}
	return 0;
}

SYS_INIT(prng_init, APPLICATION, CONFIG_APPLICATION_INIT_PRIORITY);
```

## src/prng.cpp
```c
/*
 * Copyright (c) 2018 Google LLC.
 *
 * SPDX-License-Identifier: Apache-2.0
 */

#include <device.h>
#include <init.h>
#include <misc/byteorder.h>
#include <net/buf.h>
#include <string.h>
#include <zephyr.h>

extern "C" {
#include <mbedtls/ctr_drbg.h>
#include <mbedtls/entropy.h>
}

#include "prng.h"

struct prng_data {
	mbedtls_entropy_context entropy;
	mbedtls_ctr_drbg_context ctr_drbg;
	u32_t personalization[6];
};

static struct prng_data data;

static int prng_init(struct device *dev)
{
	int err;

	prng_board_init();

	mbedtls_entropy_init(&data.entropy);

	err = mbedtls_ctr_drbg_seed(
		&data.ctr_drbg, mbedtls_entropy_func, &data.entropy,
		(const unsigned char *)data.personalization,
		sizeof(data.personalization));

	if (err != 0) {
		return err;
	}

	return 0;
}

SYS_INIT(prng_init, APPLICATION, CONFIG_APPLICATION_INIT_PRIORITY);
```

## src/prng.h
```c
/*
 * Copyright (c) 2018 Google LLC.
 *
 * SPDX-License-Identifier: Apache-2.0
 */

#pragma once

#include <sys/types.h>

void prng_add_entropy(u32_t ch);
void prng_feed();
void prng_board_init();
```
